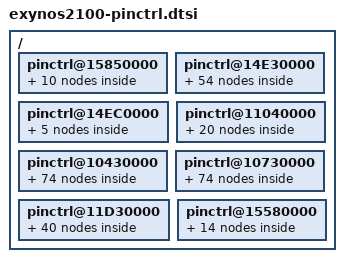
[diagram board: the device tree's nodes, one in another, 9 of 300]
/*
 * Samsung's Exynos2100 SoC pin-mux and pin-config device tree source
 *
 * Copyright (c) 2019 Samsung Electronics Co., Ltd.
 *		http://www.samsung.com
 *
 * Samsung's Exynos2100 SoC pin-mux and pin-config options are listed as device
 * tree nodes are listed in this file.
 *
 * This program is free software; you can redistribute it and/or modify
 * it under the terms of the GNU General Public License version 2 as
 * published by the Free Software Foundation.
*/

/ {
	/* ALIVE */
	pinctrl@15850000 {
		gpq0: gpq0 {
			gpio-controller;
			#gpio-cells = <2>;
		};
		gpq1: gpq1 {
			gpio-controller;
			#gpio-cells = <2>;
		};
		gpq2: gpq2 {
			gpio-controller;
			#gpio-cells = <2>;
		};
		gpb5: gpb5 {
			gpio-controller;
			#gpio-cells = <2>;
		};

		/* USI_UART_BT */
		uart1_bus_single: uart1-bus {
			samsung,pins = "gpq0-3", "gpq0-2", "gpq0-1", "gpq0-0";
			samsung,pin-function = <2>;
			samsung,pin-pud = <3>;
		};

		uart1_bus_rts: uart1-bus-rts {
			samsung,pins = "gpq0-2";
			samsung,pin-function = <1>;
			samsung,pin-pud = <0>;
			samsung,pin-val = <1>;
		};

		uart1_bus_tx_dat: uart1-bus-tx-dat {
			samsung,pins = "gpq0-1";
			samsung,pin-val = <1>;
		};

		uart1_bus_tx_con: uart1-bus-tx-con {
			samsung,pins = "gpq0-1";
			samsung,pin-function = <1>;
		};

		aud_i2s5_bus:aud-i2s5-bus {
			samsung,pins = "gpb5-0", "gpb5-1", "gpb5-2", "gpb5-3";
			samsung,pin-function = <3>;
			samsung,pin-pud = <0>;
		};

		aud_i2s5_idle:aud-i2s5-idle {
			samsung,pins = "gpb5-0", "gpb5-1", "gpb5-2", "gpb5-3";
			samsung,pin-function = <0>;
			samsung,pin-pud = <1>;
		};
	};

	/* CMGP */
	pinctrl@14E30000{
		gpm0: gpm0 {
			gpio-controller;
			#gpio-cells = <2>;

			interrupt-controller;
			#interrupt-cells = <2>;
			interrupt-parent = <&gic>;
			interrupts = <GIC_SPI INTREQ__EXT_INTM00 IRQ_TYPE_LEVEL_HIGH>,
				     <GIC_SPI INTREQ__EXT_INTM01 IRQ_TYPE_LEVEL_HIGH>;
		};

		gpm1: gpm1 {
			gpio-controller;
			#gpio-cells = <2>;

			interrupt-controller;
			#interrupt-cells = <2>;
			interrupt-parent = <&gic>;
			interrupts = <GIC_SPI INTREQ__EXT_INTM02 IRQ_TYPE_LEVEL_HIGH>,
				     <GIC_SPI INTREQ__EXT_INTM03 IRQ_TYPE_LEVEL_HIGH>;
		};

		gpm2: gpm2 {
			gpio-controller;
			#gpio-cells = <2>;

			interrupt-controller;
			#interrupt-cells = <2>;
			interrupt-parent = <&gic>;
			interrupts = <GIC_SPI INTREQ__EXT_INTM04 IRQ_TYPE_LEVEL_HIGH>,
				     <GIC_SPI INTREQ__EXT_INTM05 IRQ_TYPE_LEVEL_HIGH>;
		};

		gpm3: gpm3 {
			gpio-controller;
			#gpio-cells = <2>;

			interrupt-controller;
			#interrupt-cells = <2>;
			interrupt-parent = <&gic>;
			interrupts = <GIC_SPI INTREQ__EXT_INTM06 IRQ_TYPE_LEVEL_HIGH>,
				     <GIC_SPI INTREQ__EXT_INTM07 IRQ_TYPE_LEVEL_HIGH>;
		};

		gpm4: gpm4 {
			gpio-controller;
			#gpio-cells = <2>;

			interrupt-controller;
			#interrupt-cells = <2>;
			interrupt-parent = <&gic>;
			interrupts = <GIC_SPI INTREQ__EXT_INTM08 IRQ_TYPE_LEVEL_HIGH>,
				     <GIC_SPI INTREQ__EXT_INTM09 IRQ_TYPE_LEVEL_HIGH>;
		};

		gpm5: gpm5 {
			gpio-controller;
			#gpio-cells = <2>;

			interrupt-controller;
			#interrupt-cells = <2>;
			interrupt-parent = <&gic>;
			interrupts = <GIC_SPI INTREQ__EXT_INTM10 IRQ_TYPE_LEVEL_HIGH>,
				     <GIC_SPI INTREQ__EXT_INTM11 IRQ_TYPE_LEVEL_HIGH>;
		};

		gpm6: gpm6 {
			gpio-controller;
			#gpio-cells = <2>;

			interrupt-controller;
			#interrupt-cells = <2>;
			interrupt-parent = <&gic>;
			interrupts = <GIC_SPI INTREQ__EXT_INTM12 IRQ_TYPE_LEVEL_HIGH>,
				     <GIC_SPI INTREQ__EXT_INTM13 IRQ_TYPE_LEVEL_HIGH>;
		};

		gpm7: gpm7 {
			gpio-controller;
			#gpio-cells = <2>;

			interrupt-controller;
			#interrupt-cells = <2>;
			interrupt-parent = <&gic>;
			interrupts = <GIC_SPI INTREQ__EXT_INTM14 IRQ_TYPE_LEVEL_HIGH>,
				     <GIC_SPI INTREQ__EXT_INTM15 IRQ_TYPE_LEVEL_HIGH>;
		};

		gpm8: gpm8 {
			gpio-controller;
			#gpio-cells = <2>;

			interrupt-controller;
			#interrupt-cells = <2>;
			interrupt-parent = <&gic>;
			interrupts = <GIC_SPI INTREQ__EXT_INTM16 IRQ_TYPE_LEVEL_HIGH>;
		};

		gpm9: gpm9 {
			gpio-controller;
			#gpio-cells = <2>;

			interrupt-controller;
			#interrupt-cells = <2>;
			interrupt-parent = <&gic>;
			interrupts = <GIC_SPI INTREQ__EXT_INTM17 IRQ_TYPE_LEVEL_HIGH>;
		};

		gpm10: gpm10 {
			gpio-controller;
			#gpio-cells = <2>;

			interrupt-controller;
			#interrupt-cells = <2>;
			interrupt-parent = <&gic>;
			interrupts = <GIC_SPI INTREQ__EXT_INTM18 IRQ_TYPE_LEVEL_HIGH>;
		};

		gpm11: gpm11 {
			gpio-controller;
			#gpio-cells = <2>;

			interrupt-controller;
			#interrupt-cells = <2>;
			interrupt-parent = <&gic>;
			interrupts = <GIC_SPI INTREQ__EXT_INTM19 IRQ_TYPE_LEVEL_HIGH>;
		};

		gpm12: gpm12 {
			gpio-controller;
			#gpio-cells = <2>;

			interrupt-controller;
			#interrupt-cells = <2>;
			interrupt-parent = <&gic>;
			interrupts = <GIC_SPI INTREQ__EXT_INTM20 IRQ_TYPE_LEVEL_HIGH>;
		};

		gpm13: gpm13 {
			gpio-controller;
			#gpio-cells = <2>;

			interrupt-controller;
			#interrupt-cells = <2>;
			interrupt-parent = <&gic>;
			interrupts = <GIC_SPI INTREQ__EXT_INTM21 IRQ_TYPE_LEVEL_HIGH>;
		};

		gpm14: gpm14 {
			gpio-controller;
			#gpio-cells = <2>;

			interrupt-controller;
			#interrupt-cells = <2>;
			interrupt-parent = <&gic>;
			interrupts = <GIC_SPI INTREQ__EXT_INTM22 IRQ_TYPE_LEVEL_HIGH>;
		};

		gpm15: gpm15 {
			gpio-controller;
			#gpio-cells = <2>;

			interrupt-controller;
			#interrupt-cells = <2>;
			interrupt-parent = <&gic>;
			interrupts = <GIC_SPI INTREQ__EXT_INTM23 IRQ_TYPE_LEVEL_HIGH>;
		};

		gpm16: gpm16 {
			gpio-controller;
			#gpio-cells = <2>;

			interrupt-controller;
			#interrupt-cells = <2>;
			interrupt-parent = <&gic>;
			interrupts = <GIC_SPI INTREQ__EXT_INTM24 IRQ_TYPE_LEVEL_HIGH>;
		};

		gpm17: gpm17 {
			gpio-controller;
			#gpio-cells = <2>;

			interrupt-controller;
			#interrupt-cells = <2>;
			interrupt-parent = <&gic>;
			interrupts = <GIC_SPI INTREQ__EXT_INTM25 IRQ_TYPE_LEVEL_HIGH>;
		};

		gpm18: gpm18 {
			gpio-controller;
			#gpio-cells = <2>;

			interrupt-controller;
			#interrupt-cells = <2>;
			interrupt-parent = <&gic>;
			interrupts = <GIC_SPI INTREQ__EXT_INTM26 IRQ_TYPE_LEVEL_HIGH>;
		};

		gpm19: gpm19 {
			gpio-controller;
			#gpio-cells = <2>;

			interrupt-controller;
			#interrupt-cells = <2>;
			interrupt-parent = <&gic>;
			interrupts = <GIC_SPI INTREQ__EXT_INTM27 IRQ_TYPE_LEVEL_HIGH>;
		};

		gpm20: gpm20 {
			gpio-controller;
			#gpio-cells = <2>;

			interrupt-controller;
			#interrupt-cells = <2>;
			interrupt-parent = <&gic>;
			interrupts = <GIC_SPI INTREQ__EXT_INTM28 IRQ_TYPE_LEVEL_HIGH>;
		};

		gpm21: gpm21 {
			gpio-controller;
			#gpio-cells = <2>;

			interrupt-controller;
			#interrupt-cells = <2>;
			interrupt-parent = <&gic>;
			interrupts = <GIC_SPI INTREQ__EXT_INTM29 IRQ_TYPE_LEVEL_HIGH>;
		};

		gpm22: gpm22 {
			gpio-controller;
			#gpio-cells = <2>;

			interrupt-controller;
			#interrupt-cells = <2>;
			interrupt-parent = <&gic>;
			interrupts = <GIC_SPI INTREQ__EXT_INTM30 IRQ_TYPE_LEVEL_HIGH>;
		};

		gpm23: gpm23 {
			gpio-controller;
			#gpio-cells = <2>;

			interrupt-controller;
			#interrupt-cells = <2>;
			interrupt-parent = <&gic>;
			interrupts = <GIC_SPI INTREQ__EXT_INTM31 IRQ_TYPE_LEVEL_HIGH>;
		};

		gpm24: gpm24 {
			gpio-controller;
			#gpio-cells = <2>;

			interrupt-controller;
			#interrupt-cells = <2>;
			interrupt-parent = <&gic>;
			interrupts = <GIC_SPI INTREQ__EXT_INTM32 IRQ_TYPE_LEVEL_HIGH>;
		};

		gpm25: gpm25 {
			gpio-controller;
			#gpio-cells = <2>;

			interrupt-controller;
			#interrupt-cells = <2>;
			interrupt-parent = <&gic>;
			interrupts = <GIC_SPI INTREQ__EXT_INTM33 IRQ_TYPE_LEVEL_HIGH>;
		};

		/* usi_cmgp00 */
		hsi2c38_bus: hsi2c38-bus {
			samsung,pins = "gpm0-0", "gpm0-1";
			samsung,pin-function = <2>;
			samsung,pin-pud = <0>;
			samsung,pin-drv = <0>;
		};

		/* usi_cmgp00_i2c */
		hsi2c39_bus: hsi2c39-bus {
			samsung,pins = "gpm1-0", "gpm1-1";
			samsung,pin-function = <3>;
			samsung,pin-pud = <0>;
			samsung,pin-drv = <0>;
		};

		/* usi_cmgp01 */
		hsi2c40_bus: hsi2c40-bus {
			samsung,pins = "gpm2-0", "gpm2-1";
			samsung,pin-function = <2>;
			samsung,pin-pud = <0>;
			samsung,pin-drv = <0>;
		};

		/* usi_cmgp01_i2c */
		hsi2c41_bus: hsi2c41-bus {
			samsung,pins = "gpm3-0", "gpm3-1";
			samsung,pin-function = <3>;
			samsung,pin-pud = <0>;
			samsung,pin-drv = <0>;
		};

		/* usi_cmgp02 */
		hsi2c42_bus: hsi2c42-bus {
			samsung,pins = "gpm4-0", "gpm4-1";
			samsung,pin-function = <2>;
			samsung,pin-pud = <0>;
			samsung,pin-drv = <0>;
		};

		/* usi_cmgp02_i2c */
		hsi2c43_bus: hsi2c43-bus {
			samsung,pins = "gpm5-0", "gpm5-1";
			samsung,pin-function = <3>;
			samsung,pin-pud = <0>;
			samsung,pin-drv = <0>;
		};

		/* usi_cmgp03 */
		hsi2c44_bus: hsi2c44-bus {
			samsung,pins = "gpm6-0", "gpm6-1";
			samsung,pin-function = <2>;
			samsung,pin-pud = <0>;
			samsung,pin-drv = <0>;
		};

		/* usi_cmgp03_i2c */
		hsi2c45_bus: hsi2c45-bus {
			samsung,pins = "gpm7-0", "gpm7-1";
			samsung,pin-function = <3>;
			samsung,pin-pud = <0>;
			samsung,pin-drv = <0>;
		};

		/* spi usi_cmgp00 */
		spi19_bus: spi19-bus {
			samsung,pins = "gpm0-0", "gpm0-1", "gpm1-0";
			samsung,pin-function = <2>;
			samsung,pin-pud = <0>;
			samsung,pin-drv = <0>;
		};

		spi19_cs: spi19-cs {
			samsung,pins = "gpm1-1";
			samsung,pin-function = <1>;
			samsung,pin-pud = <0>;
			samsung,pin-drv = <0>;
		};

		spi19_cs_func: spi19-cs-func {
			samsung,pins = "gpm1-1";
			samsung,pin-function = <2>;
			samsung,pin-pud = <0>;
			samsung,pin-drv = <0>;
		};

		/* spi usi_cmgp01 */
		spi20_bus: spi20-bus {
			samsung,pins = "gpm2-0", "gpm2-1", "gpm3-0";
			samsung,pin-function = <2>;
			samsung,pin-pud = <0>;
			samsung,pin-drv = <0>;
		};

		spi20_cs: spi20-cs {
			samsung,pins = "gpm3-1";
			samsung,pin-function = <1>;
			samsung,pin-pud = <0>;
			samsung,pin-drv = <0>;
		};

		spi20_cs_func: spi20-cs-func {
			samsung,pins = "gpm3-1";
			samsung,pin-function = <2>;
			samsung,pin-pud = <0>;
			samsung,pin-drv = <0>;
		};

		/* spi usi_cmgp02 */
		spi21_bus: spi21-bus {
			samsung,pins = "gpm4-0", "gpm4-1", "gpm5-0";
			samsung,pin-function = <2>;
			samsung,pin-pud = <0>;
			samsung,pin-drv = <0>;
		};

		spi21_cs: spi21-cs {
			samsung,pins = "gpm5-1";
			samsung,pin-function = <1>;
			samsung,pin-pud = <0>;
			samsung,pin-drv = <0>;
		};

		spi21_cs_func: spi21-cs-func {
			samsung,pins = "gpm5-1";
			samsung,pin-function = <2>;
			samsung,pin-pud = <0>;
			samsung,pin-drv = <0>;
		};

		/* spi usi_cmgp03 */
		spi22_bus: spi22-bus {
			samsung,pins = "gpm6-0", "gpm6-1", "gpm7-0";
			samsung,pin-function = <2>;
			samsung,pin-pud = <0>;
			samsung,pin-drv = <0>;
		};

		spi22_cs: spi22-cs {
			samsung,pins = "gpm7-1";
			samsung,pin-function = <1>;
			samsung,pin-pud = <0>;
			samsung,pin-drv = <0>;
		};

		spi22_cs_func: spi22-cs-func {
			samsung,pins = "gpm7-1";
			samsung,pin-function = <2>;
			samsung,pin-pud = <0>;
			samsung,pin-drv = <0>;
		};

		/* usi_cmgp00_uart */
		uart21_bus_single: uart21-bus {
			samsung,pins = "gpm0-0", "gpm0-1", "gpm2-0", "gpm2-1";
			samsung,pin-function = <2>;
			samsung,pin-pud = <0>;
		};

		uart21_bus_dual: uart21-bus-dual {
			samsung,pins = "gpm0-0", "gpm0-1";
			samsung,pin-function = <2>;
			samsung,pin-pud = <0>;
		};

		/* usi_cmgp01_uart */
		uart22_bus_single: uart22-bus {
			samsung,pins = "gpm3-0", "gpm3-1", "gpm4-0", "gpm4-1";
			samsung,pin-function = <2>;
			samsung,pin-pud = <0>;
		};

		uart22_bus_dual: uart22-bus-dual {
			samsung,pins = "gpm3-0", "gpm3-1";
			samsung,pin-function = <2>;
			samsung,pin-pud = <0>;
		};

		/* usi_cmgp02_uart */
		uart23_bus_single: uart23-bus {
			samsung,pins = "gpm5-0", "gpm5-1", "gpm6-0", "gpm6-1";
			samsung,pin-function = <2>;
			samsung,pin-pud = <0>;
		};

		uart23_bus_dual: uart23-bus-dual {
			samsung,pins = "gpm5-0", "gpm5-1";
			samsung,pin-function = <2>;
			samsung,pin-pud = <0>;
		};

		/* usi_cmgp03_uart */
		uart24_bus_single: uart24-bus {
			samsung,pins = "gpm7-0", "gpm7-1", "gpm8-0", "gpm8-1";
			samsung,pin-function = <2>;
			samsung,pin-pud = <0>;
		};

		uart24_bus_dual: uart24-bus-dual {
			samsung,pins = "gpm7-0", "gpm7-1";
			samsung,pin-function = <2>;
			samsung,pin-pud = <0>;
		};
	};

	/* CMGPEINT */
	pinctrl@14EC0000{
		gpa0: gpa0 {
			gpio-controller;
			#gpio-cells = <2>;

			interrupt-controller;
			#interrupt-cells = <3>;
			interrupt-parent = <&gic>;
			interrupts = <GIC_SPI EXT_INTA0_OUT0 IRQ_TYPE_LEVEL_HIGH>, <GIC_SPI EXT_INTA0_OUT1 IRQ_TYPE_LEVEL_HIGH>,
				     <GIC_SPI EXT_INTA0_OUT2 IRQ_TYPE_LEVEL_HIGH>, <GIC_SPI EXT_INTA0_OUT3 IRQ_TYPE_LEVEL_HIGH>,
				     <GIC_SPI EXT_INTA0_OUT4 IRQ_TYPE_LEVEL_HIGH>, <GIC_SPI EXT_INTA0_OUT5 IRQ_TYPE_LEVEL_HIGH>,
				     <GIC_SPI EXT_INTA0_OUT6 IRQ_TYPE_LEVEL_HIGH>, <GIC_SPI EXT_INTA0_OUT7 IRQ_TYPE_LEVEL_HIGH>;
		};

		gpa1: gpa1 {
			gpio-controller;
			#gpio-cells = <2>;

			interrupt-controller;
			#interrupt-cells = <3>;
			interrupt-parent = <&gic>;
			interrupts = <GIC_SPI EXT_INTA1_OUT0 IRQ_TYPE_LEVEL_HIGH>, <GIC_SPI EXT_INTA1_OUT1 IRQ_TYPE_LEVEL_HIGH>,
				     <GIC_SPI EXT_INTA1_OUT2 IRQ_TYPE_LEVEL_HIGH>, <GIC_SPI EXT_INTA1_OUT3 IRQ_TYPE_LEVEL_HIGH>,
				     <GIC_SPI EXT_INTA1_OUT4 IRQ_TYPE_LEVEL_HIGH>, <GIC_SPI EXT_INTA1_OUT5 IRQ_TYPE_LEVEL_HIGH>,
				     <GIC_SPI EXT_INTA1_OUT6 IRQ_TYPE_LEVEL_HIGH>, <GIC_SPI EXT_INTA1_OUT7 IRQ_TYPE_LEVEL_HIGH>;
		};

		gpa2: gpa2 {
			gpio-controller;
			#gpio-cells = <2>;

			interrupt-controller;
			#interrupt-cells = <3>;
			interrupt-parent = <&gic>;
			interrupts = <GIC_SPI EXT_INTA2_OUT0 IRQ_TYPE_LEVEL_HIGH>, <GIC_SPI EXT_INTA2_OUT1 IRQ_TYPE_LEVEL_HIGH>,
				     <GIC_SPI EXT_INTA2_OUT2 IRQ_TYPE_LEVEL_HIGH>, <GIC_SPI EXT_INTA2_OUT3 IRQ_TYPE_LEVEL_HIGH>,
				     <GIC_SPI EXT_INTA2_OUT4 IRQ_TYPE_LEVEL_HIGH>, <GIC_SPI EXT_INTA2_OUT5 IRQ_TYPE_LEVEL_HIGH>,
				     <GIC_SPI EXT_INTA2_OUT6 IRQ_TYPE_LEVEL_HIGH>, <GIC_SPI EXT_INTA2_OUT7 IRQ_TYPE_LEVEL_HIGH>;
		};

		gpa3: gpa3 {
			gpio-controller;
			#gpio-cells = <2>;

			interrupt-controller;
			#interrupt-cells = <3>;
			interrupt-parent = <&gic>;
			interrupts = <GIC_SPI EXT_INTA3_OUT0 IRQ_TYPE_LEVEL_HIGH>, <GIC_SPI EXT_INTA3_OUT1 IRQ_TYPE_LEVEL_HIGH>,
				     <GIC_SPI EXT_INTA3_OUT2 IRQ_TYPE_LEVEL_HIGH>, <GIC_SPI EXT_INTA3_OUT3 IRQ_TYPE_LEVEL_HIGH>,
				     <GIC_SPI EXT_INTA3_OUT4 IRQ_TYPE_LEVEL_HIGH>, <GIC_SPI EXT_INTA3_OUT5 IRQ_TYPE_LEVEL_HIGH>,
				     <GIC_SPI EXT_INTA3_OUT6 IRQ_TYPE_LEVEL_HIGH>, <GIC_SPI EXT_INTA3_OUT7 IRQ_TYPE_LEVEL_HIGH>;
		};

		gpa4: gpa4 {
			gpio-controller;
			#gpio-cells = <2>;

			interrupt-controller;
			#interrupt-cells = <3>;
			interrupt-parent = <&gic>;
			interrupts = <GIC_SPI EXT_INTA4_OUT0 IRQ_TYPE_LEVEL_HIGH>, <GIC_SPI EXT_INTA4_OUT1 IRQ_TYPE_LEVEL_HIGH>;
		};
	};

	/* HSI1 */
	pinctrl@11040000 {
		gpf0: gpf0 {
			gpio-controller;
			#gpio-cells = <2>;

			interrupt-controller;
			#interrupt-cells = <2>;
		};

		gpf1: gpf1 {
			gpio-controller;
			#gpio-cells = <2>;

			interrupt-controller;
			#interrupt-cells = <2>;
		};

		gpf2: gpf2 {
			gpio-controller;
			#gpio-cells = <2>;

			interrupt-controller;
			#interrupt-cells = <2>;
		};

		pcie0_clkreq: pcie0_clkreq {
		      samsung,pins = "gpf0-0";
		      samsung,pin-function = <2>;
		      samsung,pin-pud = <3>;
		      samsung,pin-drv = <3>;
		      samsung,pin-con-pdn = <3>;
		      samsung,pin-pud-pdn = <3>;
		};

		pcie0_perst: pcie0_perst {
		     samsung,pins = "gpf0-1";
		     samsung,pin-function = <1>;
		     samsung,pin-drv = <3>;
		     samsung,pin-con-pdn = <3>;
		};

		pcie1_clkreq: pcie1_clkreq {
		      samsung,pins = "gpf0-2";
		      samsung,pin-function = <2>;
		      samsung,pin-pud = <3>;
		      samsung,pin-drv = <3>;
		      samsung,pin-con-pdn = <3>;
		      samsung,pin-pud-pdn = <3>;
		};

		pcie1_perst: pcie1_perst {
		     samsung,pins = "gpf0-3";
		     samsung,pin-function = <1>;
		     samsung,pin-drv = <3>;
		     samsung,pin-con-pdn = <3>;
		};

		ufs_rst_n: ufs-rst-n {
			samsung,pins = "gpf2-1";
			samsung,pin-function = <2>;
			samsung,pin-pud = <0>;
			samsung,pin-con-pdn = <3>;
			samsung,pin-pud-pdn = <0>;
		};

		ufs_refclk_out: ufs-refclk-out {
			samsung,pins = "gpf2-0";
			samsung,pin-function = <2>;
			samsung,pin-pud = <0>;
			samsung,pin-con-pdn = <3>;
			samsung,pin-drv = <1>;
			samsung,pin-pud-pdn = <0>;
		};

		sd2_clk: sd2-clk {
			samsung,pins = "gpf1-0";
			samsung,pin-function = <2>;
			samsung,pin-pud = <0>;
			samsung,pin-drv = <2>;
		};

		sd2_cmd: sd2-cmd {
			samsung,pins = "gpf1-1";
			samsung,pin-function = <2>;
			samsung,pin-pud = <3>;
			samsung,pin-drv = <2>;
		};

		sd2_bus1: sd2-bus-width1 {
			samsung,pins = "gpf1-2";
			samsung,pin-function = <2>;
			samsung,pin-pud = <3>;
			samsung,pin-drv = <2>;
		};

		sd2_bus4: sd2-bus-width4 {
			samsung,pins = "gpf1-3", "gpf1-4", "gpf1-5";
			samsung,pin-function = <2>;
			samsung,pin-pud = <3>;
			samsung,pin-drv = <2>;
		};

		sd2_clk_fast_slew_rate_1x: sd2-clk_fast_slew_rate_1x {
			samsung,pins = "gpf1-0";
			samsung,pin-function = <2>;
			samsung,pin-pud = <0>;
			samsung,pin-drv = <0>;
		};

		sd2_clk_fast_slew_rate_1_5x: sd2-clk_fast_slew_rate_1_5x {
			samsung,pins = "gpf1-0";
			samsung,pin-function = <2>;
			samsung,pin-pud = <0>;
			samsung,pin-drv = <1>;
		};

		sd2_clk_fast_slew_rate_2x: sd2-clk_fast_slew_rate_2x {
			samsung,pins = "gpf1-0";
			samsung,pin-function = <2>;
			samsung,pin-pud = <0>;
			samsung,pin-drv = <2>;
		};

		sd2_clk_fast_slew_rate_2_5x: sd2-clk_fast_slew_rate_2_5x {
			samsung,pins = "gpf1-0";
			samsung,pin-function = <2>;
			samsung,pin-pud = <0>;
			samsung,pin-drv = <3>;
		};

		sd2_clk_fast_slew_rate_3x: sd2-clk_fast_slew_rate_3x {
			samsung,pins = "gpf1-0";
			samsung,pin-function = <2>;
			samsung,pin-pud = <0>;
			samsung,pin-drv = <4>;
		};

		sd2_clk_fast_slew_rate_4x: sd2-clk_fast_slew_rate_4x {
			samsung,pins = "gpf1-0";
			samsung,pin-function = <2>;
			samsung,pin-pud = <0>;
			samsung,pin-drv = <5>;
		};

		sd2_pins_as_pdn: sd2-pins-as-pdn {
			samsung,pins = "gpf1-0", "gpf1-1", "gpf1-2", "gpf1-3", "gpf1-4", "gpf1-5";
			samsung,pin-function = <0>;
			samsung,pin-pud = <2>;
		};

	};

	/* PERIC0 */
	pinctrl@10430000 {
		gpp0: gpp0 {
			gpio-controller;
			#gpio-cells = <2>;

			interrupt-controller;
			#interrupt-cells = <2>;
		};

		gpp1: gpp1 {
			gpio-controller;
			#gpio-cells = <2>;

			interrupt-controller;
			#interrupt-cells = <2>;
		};

		gpp2: gpp2 {
			gpio-controller;
			#gpio-cells = <2>;

			interrupt-controller;
			#interrupt-cells = <2>;
		};

		gpp3: gpp3 {
			gpio-controller;
			#gpio-cells = <2>;

			interrupt-controller;
			#interrupt-cells = <2>;
		};

		gpp4: gpp4 {
			gpio-controller;
			#gpio-cells = <2>;

			interrupt-controller;
			#interrupt-cells = <2>;
		};

		gpp5: gpp5 {
			gpio-controller;
			#gpio-cells = <2>;

			interrupt-controller;
			#interrupt-cells = <2>;
		};

		gpp13: gpp13 {
			gpio-controller;
			#gpio-cells = <2>;

			interrupt-controller;
			#interrupt-cells = <2>;
		};

		gpp14: gpp14 {
			gpio-controller;
			#gpio-cells = <2>;

			interrupt-controller;
			#interrupt-cells = <2>;
		};

		gpp15: gpp15 {
			gpio-controller;
			#gpio-cells = <2>;

			interrupt-controller;
			#interrupt-cells = <2>;
		};

		gpg0: gpg0 {
			gpio-controller;
			#gpio-cells = <2>;

			interrupt-controller;
			#interrupt-cells = <2>;
		};

		/* USI_PERIC0_UART_DBG */
		uart0_bus: uart0-bus {
			samsung,pins = "gpg0-2", "gpg0-3";
			samsung,pin-function = <3>;
			samsung,pin-pud = <3>;
		};

		/* PERIC0 USI00 */
		hsi2c0_bus: hsi2c0-bus {
			samsung,pins = "gpp0-0", "gpp0-1";
			samsung,pin-function = <2>;
			samsung,pin-pud = <0>;
			samsung,pin-drv = <0>;
		};

		/* PERIC0 USI00_I2C */
		hsi2c1_bus: hsi2c1-bus {
			samsung,pins = "gpp0-2", "gpp0-3";
			samsung,pin-function = <3>;
			samsung,pin-pud = <0>;
			samsung,pin-drv = <0>;
		};

		/* PERIC0 USI01 */
		hsi2c2_bus: hsi2c2-bus {
			samsung,pins = "gpp1-0", "gpp1-1";
			samsung,pin-function = <2>;
			samsung,pin-pud = <0>;
			samsung,pin-drv = <0>;
		};

		/* PERIC0 USI01_I2C */
		hsi2c3_bus: hsi2c3-bus {
			samsung,pins = "gpp1-2", "gpp1-3";
			samsung,pin-function = <3>;
			samsung,pin-pud = <0>;
			samsung,pin-drv = <0>;
		};

		/* PERIC0 USI02 */
		hsi2c4_bus: hsi2c4-bus {
			samsung,pins = "gpp2-0", "gpp2-1";
			samsung,pin-function = <2>;
			samsung,pin-pud = <0>;
			samsung,pin-drv = <0>;
		};

		/* PERIC0 USI02_I2C */
		hsi2c5_bus: hsi2c5-bus {
			samsung,pins = "gpp2-2", "gpp2-3";
			samsung,pin-function = <3>;
			samsung,pin-pud = <0>;
			samsung,pin-drv = <0>;
		};

		/* PERIC0 USI03 */
		hsi2c6_bus: hsi2c6-bus {
			samsung,pins = "gpp3-0", "gpp3-1";
			samsung,pin-function = <2>;
			samsung,pin-pud = <0>;
			samsung,pin-drv = <0>;
		};

		/* PERIC0 USI03_I2C */
		hsi2c7_bus: hsi2c7-bus {
			samsung,pins = "gpp3-2", "gpp3-3";
			samsung,pin-function = <3>;
			samsung,pin-pud = <0>;
			samsung,pin-drv = <0>;
		};

		/* PERIC0 USI04 */
		hsi2c8_bus: hsi2c8-bus {
			samsung,pins = "gpp4-0", "gpp4-1";
			samsung,pin-function = <2>;
			samsung,pin-pud = <0>;
			samsung,pin-drv = <0>;
		};

		/* PERIC0 USI04_I2C */
		hsi2c9_bus: hsi2c9-bus {
			samsung,pins = "gpp4-2", "gpp4-3";
			samsung,pin-function = <3>;
			samsung,pin-pud = <0>;
			samsung,pin-drv = <0>;
		};

		/* PERIC0 USI05 */
		hsi2c10_bus: hsi2c10-bus {
			samsung,pins = "gpp5-0", "gpp5-1";
			samsung,pin-function = <2>;
			samsung,pin-pud = <0>;
			samsung,pin-drv = <0>;
		};

		/* PERIC0 USI05_I2C */
		hsi2c11_bus: hsi2c11-bus {
			samsung,pins = "gpp5-2", "gpp5-3";
			samsung,pin-function = <3>;
			samsung,pin-pud = <0>;
			samsung,pin-drv = <0>;
		};

		/* PERIC0 USI13 */
		hsi2c26_bus: hsi2c26-bus {
			samsung,pins = "gpp13-0", "gpp13-1";
			samsung,pin-function = <2>;
			samsung,pin-pud = <0>;
			samsung,pin-drv = <0>;
		};

		/* PERIC0 USI13_I2C */
		hsi2c27_bus: hsi2c27-bus {
			samsung,pins = "gpp13-2", "gpp13-3";
			samsung,pin-function = <3>;
			samsung,pin-pud = <0>;
			samsung,pin-drv = <0>;
		};

		/* PERIC0 USI14 */
		hsi2c28_bus: hsi2c28-bus {
			samsung,pins = "gpp14-0", "gpp14-1";
			samsung,pin-function = <2>;
			samsung,pin-pud = <0>;
			samsung,pin-drv = <0>;
		};

		/* PERIC0 USI14_I2C */
		hsi2c29_bus: hsi2c29-bus {
			samsung,pins = "gpp14-2", "gpp14-3";
			samsung,pin-function = <3>;
			samsung,pin-pud = <0>;
			samsung,pin-drv = <0>;
		};

		/* PERIC0 USI15 */
		hsi2c30_bus: hsi2c30-bus {
			samsung,pins = "gpp15-0", "gpp15-1";
			samsung,pin-function = <2>;
			samsung,pin-pud = <0>;
			samsung,pin-drv = <0>;
		};

		/* PERIC0 USI15_I2C */
		hsi2c31_bus: hsi2c31-bus {
			samsung,pins = "gpp15-2", "gpp15-3";
			samsung,pin-function = <3>;
			samsung,pin-pud = <0>;
			samsung,pin-drv = <0>;
		};

		/* SPI USI_PERIC0_USI00_SPI */
		spi0_bus: spi0-bus {
			samsung,pins = "gpp0-2", "gpp0-1", "gpp0-0";
			samsung,pin-function = <2>;
			samsung,pin-pud = <0>;
			samsung,pin-drv = <0>;
		};

		spi0_cs: spi0-cs {
			samsung,pins = "gpp0-3";
			samsung,pin-function = <1>;
			samsung,pin-pud = <0>;
			samsung,pin-drv = <0>;
		};

		spi0_cs_func: spi0-cs-func {
			samsung,pins = "gpp0-3";
			samsung,pin-function = <2>;
			samsung,pin-pud = <0>;
			samsung,pin-drv = <0>;
		};

		/* PERIC0 USI01_SPI */
		spi1_bus: spi1-bus {
			samsung,pins = "gpp1-2", "gpp1-1", "gpp1-0";
			samsung,pin-function = <2>;
			samsung,pin-pud = <0>;
			samsung,pin-drv = <0>;
		};

		spi1_cs: spi1-cs {
			samsung,pins = "gpp1-3";
			samsung,pin-function = <1>;
			samsung,pin-pud = <0>;
			samsung,pin-drv = <0>;
		};

		spi1_cs_func: spi1-cs-func {
			samsung,pins = "gpp1-3";
			samsung,pin-function = <2>;
			samsung,pin-pud = <0>;
			samsung,pin-drv = <0>;
		};

		/* PERIC0 USI02_SPI */
		spi2_bus: spi2-bus {
			samsung,pins = "gpp2-2", "gpp2-1", "gpp2-0";
			samsung,pin-function = <2>;
			samsung,pin-pud = <0>;
			samsung,pin-drv = <0>;
		};

		spi2_cs: spi2-cs {
			samsung,pins = "gpp2-3";
			samsung,pin-function = <1>;
			samsung,pin-pud = <0>;
			samsung,pin-drv = <0>;
		};

		spi2_cs_func: spi2-cs-func {
			samsung,pins = "gpp2-3";
			samsung,pin-function = <2>;
			samsung,pin-pud = <0>;
			samsung,pin-drv = <0>;
		};

		/* PERIC0 USI03_SPI */
		spi3_bus: spi3-bus {
			samsung,pins = "gpp3-2", "gpp3-1", "gpp3-0";
			samsung,pin-function = <2>;
			samsung,pin-pud = <0>;
			samsung,pin-drv = <0>;
		};

		spi3_cs: spi3-cs {
			samsung,pins = "gpp3-3";
			samsung,pin-function = <1>;
			samsung,pin-pud = <0>;
			samsung,pin-drv = <0>;
		};

		spi3_cs_func: spi3-cs-func {
			samsung,pins = "gpp3-3";
			samsung,pin-function = <2>;
			samsung,pin-pud = <0>;
			samsung,pin-drv = <0>;
		};

		/* PERIC0 USI04_SPI */
		spi4_bus: spi4-bus {
			samsung,pins = "gpp4-2", "gpp4-1", "gpp4-0";
			samsung,pin-function = <2>;
			samsung,pin-pud = <0>;
			samsung,pin-drv = <0>;
		};

		spi4_cs: spi4-cs {
			samsung,pins = "gpp4-3";
			samsung,pin-function = <1>;
			samsung,pin-pud = <0>;
			samsung,pin-drv = <0>;
		};

		spi4_cs_func: spi4-cs-func {
			samsung,pins = "gpp4-3";
			samsung,pin-function = <2>;
			samsung,pin-pud = <0>;
			samsung,pin-drv = <0>;
		};

		/* PERIC0 USI05_SPI */
		spi5_bus: spi5-bus {
			samsung,pins = "gpp5-2", "gpp5-1", "gpp5-0";
			samsung,pin-function = <2>;
			samsung,pin-pud = <0>;
			samsung,pin-drv = <0>;
		};

		spi5_cs: spi5-cs {
			samsung,pins = "gpp5-3";
			samsung,pin-function = <1>;
			samsung,pin-pud = <0>;
			samsung,pin-drv = <0>;
		};

		spi5_cs_func: spi5-cs-func {
			samsung,pins = "gpp5-3";
			samsung,pin-function = <2>;
			samsung,pin-pud = <0>;
			samsung,pin-drv = <0>;
		};

		/* PERIC0 USI13_SPI */
		spi13_bus: spi13-bus {
			samsung,pins = "gpp13-2", "gpp13-1", "gpp13-0";
			samsung,pin-function = <2>;
			samsung,pin-pud = <0>;
			samsung,pin-drv = <0>;
		};

		spi13_cs: spi13-cs {
			samsung,pins = "gpp13-3";
			samsung,pin-function = <1>;
			samsung,pin-pud = <0>;
			samsung,pin-drv = <0>;
		};

		spi13_cs_func: spi13-cs-func {
			samsung,pins = "gpp13-3";
			samsung,pin-function = <2>;
			samsung,pin-pud = <0>;
			samsung,pin-drv = <0>;
		};

		/* PERIC0 USI14_SPI */
		spi14_bus: spi14-bus {
			samsung,pins = "gpp14-2", "gpp14-1", "gpp14-0";
			samsung,pin-function = <2>;
			samsung,pin-pud = <0>;
			samsung,pin-drv = <0>;
		};

		spi14_cs: spi14-cs {
			samsung,pins = "gpp14-3";
			samsung,pin-function = <1>;
			samsung,pin-pud = <0>;
			samsung,pin-drv = <0>;
		};

		spi14_cs_func: spi14-cs-func {
			samsung,pins = "gpp14-3";
			samsung,pin-function = <2>;
			samsung,pin-pud = <0>;
			samsung,pin-drv = <0>;
		};

		/* PERIC0 USI15_SPI */
		spi15_bus: spi15-bus {
			samsung,pins = "gpp15-2", "gpp15-1", "gpp15-0";
			samsung,pin-function = <2>;
			samsung,pin-pud = <0>;
			samsung,pin-drv = <0>;
		};

		spi15_cs: spi15-cs {
			samsung,pins = "gpp15-3";
			samsung,pin-function = <1>;
			samsung,pin-pud = <0>;
			samsung,pin-drv = <0>;
		};

		spi15_cs_func: spi15-cs-func {
			samsung,pins = "gpp15-3";
			samsung,pin-function = <2>;
			samsung,pin-pud = <0>;
			samsung,pin-drv = <0>;
		};

		/* USI_PERIC0_USI00_UART */
		uart2_bus_single: uart2-bus {
			samsung,pins = "gpp0-0", "gpp0-1", "gpp0-2", "gpp0-3";
			samsung,pin-function = <2>;
			samsung,pin-pud = <0>;
		};

		uart2_bus_dual: uart2-bus-dual {
			samsung,pins = "gpp0-0", "gpp0-1";
			samsung,pin-function = <2>;
			samsung,pin-pud = <0>;
		};

		/* USI_PERIC0_USI01_UART */
		uart3_bus_single: uart3-bus {
			samsung,pins = "gpp1-0", "gpp1-1", "gpp1-2", "gpp1-3";
			samsung,pin-function = <2>;
			samsung,pin-pud = <0>;
		};

		uart3_bus_dual: uart3-bus-dual {
			samsung,pins = "gpp1-0", "gpp1-1";
			samsung,pin-function = <2>;
			samsung,pin-pud = <0>;
		};

		/* USI_PERIC0_USI02_UART */
		uart4_bus_single: uart4-bus {
			samsung,pins = "gpp2-0", "gpp2-1", "gpp2-2", "gpp2-3";
			samsung,pin-function = <2>;
			samsung,pin-pud = <0>;
		};

		uart4_bus_dual: uart4-bus-dual {
			samsung,pins = "gpp2-0", "gpp2-1";
			samsung,pin-function = <2>;
			samsung,pin-pud = <0>;
		};

		/* USI_PERIC0_USI03_UART */
		uart5_bus_single: uart5-bus {
			samsung,pins = "gpp3-0", "gpp3-1", "gpp3-2", "gpp3-3";
			samsung,pin-function = <2>;
			samsung,pin-pud = <0>;
		};

		uart5_bus_dual: uart5-bus-dual {
			samsung,pins = "gpp3-0", "gpp3-1";
			samsung,pin-function = <2>;
			samsung,pin-pud = <0>;
		};

		/* USI_PERIC0_USI04_UART */
		uart6_bus_single: uart6-bus {
			samsung,pins = "gpp4-0", "gpp4-1", "gpp4-2", "gpp4-3";
			samsung,pin-function = <2>;
			samsung,pin-pud = <0>;
		};

		uart6_bus_dual: uart6-bus-dual {
			samsung,pins = "gpp4-0", "gpp4-1";
			samsung,pin-function = <2>;
			samsung,pin-pud = <0>;
		};

		/* USI_PERIC0_USI05_UART */
		uart7_bus_single: uart7-bus {
			samsung,pins = "gpp5-0", "gpp5-1", "gpp5-2", "gpp5-3";
			samsung,pin-function = <2>;
			samsung,pin-pud = <0>;
		};

		uart7_bus_dual: uart7-bus-dual {
			samsung,pins = "gpp5-0", "gpp5-1";
			samsung,pin-function = <2>;
			samsung,pin-pud = <0>;
		};

		/* USI_PERIC0_USI13_UART */
		uart15_bus_single: uart15-bus {
			samsung,pins = "gpp13-0", "gpp13-1", "gpp13-2", "gpp13-3";
			samsung,pin-function = <2>;
			samsung,pin-pud = <0>;
		};

		uart15_bus_dual: uart15-bus-dual {
			samsung,pins = "gpp13-0", "gpp13-1";
			samsung,pin-function = <2>;
			samsung,pin-pud = <0>;
		};

		/* USI_PERIC0_USI14_UART */
		uart16_bus_single: uart16-bus {
			samsung,pins = "gpp14-0", "gpp14-1", "gpp14-2", "gpp14-3";
			samsung,pin-function = <2>;
			samsung,pin-pud = <0>;
		};

		uart16_bus_dual: uart16-bus-dual {
			samsung,pins = "gpp14-0", "gpp14-1";
			samsung,pin-function = <2>;
			samsung,pin-pud = <0>;
		};

		/* USI_PERIC0_USI15_UART */
		uart17_bus_single: uart17-bus {
			samsung,pins = "gpp15-0", "gpp15-1", "gpp15-2", "gpp15-3";
			samsung,pin-function = <2>;
			samsung,pin-pud = <0>;
		};

		uart17_bus_dual: uart17-bus-dual {
			samsung,pins = "gpp15-0", "gpp15-1";
			samsung,pin-function = <2>;
			samsung,pin-pud = <0>;
		};
	};

	/* PERIC1 */
	pinctrl@10730000 {
		gpb3: gpb3 {
			gpio-controller;
			#gpio-cells = <2>;

			interrupt-controller;
			#interrupt-cells = <2>;
		};

		gpb4: gpb4 {
			gpio-controller;
			#gpio-cells = <2>;

			interrupt-controller;
			#interrupt-cells = <2>;
		};

		gpp11: gpp11 {
			gpio-controller;
			#gpio-cells = <2>;

			interrupt-controller;
			#interrupt-cells = <2>;
		};

		gpp12: gpp12 {
			gpio-controller;
			#gpio-cells = <2>;

			interrupt-controller;
			#interrupt-cells = <2>;
		};

		gpp16: gpp16 {
			gpio-controller;
			#gpio-cells = <2>;

			interrupt-controller;
			#interrupt-cells = <2>;
		};

		gpp17: gpp17 {
			gpio-controller;
			#gpio-cells = <2>;

			interrupt-controller;
			#interrupt-cells = <2>;
		};

		gpp18: gpp18 {
			gpio-controller;
			#gpio-cells = <2>;

			interrupt-controller;
			#interrupt-cells = <2>;
		};

		gpg1: gpg1 {
			gpio-controller;
			#gpio-cells = <2>;

			interrupt-controller;
			#interrupt-cells = <2>;
		};

		gpg2: gpg2 {
			gpio-controller;
			#gpio-cells = <2>;

			interrupt-controller;
			#interrupt-cells = <2>;
		};

		gpb0: gpb0 {
			gpio-controller;
			#gpio-cells = <2>;

			interrupt-controller;
			#interrupt-cells = <2>;
		};

		gpb1: gpb1 {
			gpio-controller;
			#gpio-cells = <2>;

			interrupt-controller;
			#interrupt-cells = <2>;
		};

		gpb2: gpb2 {
			gpio-controller;
			#gpio-cells = <2>;

			interrupt-controller;
			#interrupt-cells = <2>;
		};


		/* peric1 usi11 */
		hsi2c22_bus: hsi2c22-bus {
			samsung,pins = "gpp11-0", "gpp11-1";
			samsung,pin-function = <2>;
			samsung,pin-pud = <0>;
			samsung,pin-drv = <0>;
		};

		/* peric1 usi11_i2c */
		hsi2c23_bus: hsi2c23-bus {
			samsung,pins = "gpp11-2", "gpp11-3";
			samsung,pin-function = <3>;
			samsung,pin-pud = <0>;
			samsung,pin-drv = <0>;
		};

		/* PERIC1 USI12 */
		hsi2c24_bus: hsi2c24-bus {
			samsung,pins = "gpp12-0", "gpp12-1";
			samsung,pin-function = <2>;
			samsung,pin-pud = <0>;
			samsung,pin-drv = <0>;
		};

		/* PERIC1 USI12_I2C */
		hsi2c25_bus: hsi2c25-bus {
			samsung,pins = "gpp12-2", "gpp12-3";
			samsung,pin-function = <3>;
			samsung,pin-pud = <0>;
			samsung,pin-drv = <0>;
		};

		/* PERIC1 USI16 */
		hsi2c32_bus: hsi2c32-bus {
			samsung,pins = "gpp16-0", "gpp16-1";
			samsung,pin-function = <2>;
			samsung,pin-pud = <0>;
			samsung,pin-drv = <0>;
		};

		/* PERIC1 USI16_I2C */
		hsi2c33_bus: hsi2c33-bus {
			samsung,pins = "gpp16-2", "gpp16-3";
			samsung,pin-function = <3>;
			samsung,pin-pud = <0>;
			samsung,pin-drv = <0>;
		};

		/* PERIC1 USI17 */
		hsi2c34_bus: hsi2c34-bus {
			samsung,pins = "gpp17-0", "gpp17-1";
			samsung,pin-function = <2>;
			samsung,pin-pud = <0>;
			samsung,pin-drv = <0>;
		};

		/* PERIC1 USI17_I2C */
		hsi2c35_bus: hsi2c35-bus {
			samsung,pins = "gpp17-2", "gpp17-3";
			samsung,pin-function = <3>;
			samsung,pin-pud = <0>;
			samsung,pin-drv = <0>;
		};

		/* PERIC1 USI18 */
		hsi2c36_bus: hsi2c36-bus {
			samsung,pins = "gpp18-0", "gpp18-1";
			samsung,pin-function = <2>;
			samsung,pin-pud = <0>;
			samsung,pin-drv = <0>;
		};

		/* PERIC1 USI18_I2C */
		hsi2c37_bus: hsi2c37-bus {
			samsung,pins = "gpp18-2", "gpp18-3";
			samsung,pin-function = <3>;
			samsung,pin-pud = <0>;
			samsung,pin-drv = <0>;
		};

		/* PERIC1 USI11_SPI */
		spi11_bus: spi11-bus {
			samsung,pins = "gpp11-2", "gpp11-1", "gpp11-0";
			samsung,pin-function = <2>;
			samsung,pin-pud = <0>;
			samsung,pin-drv = <0>;
		};

		spi11_cs: spi11-cs {
			samsung,pins = "gpp11-3";
			samsung,pin-function = <1>;
			samsung,pin-pud = <0>;
			samsung,pin-drv = <0>;
		};

		spi11_cs_func: spi11-cs-func {
			samsung,pins = "gpp11-3";
			samsung,pin-function = <2>;
			samsung,pin-pud = <0>;
			samsung,pin-drv = <0>;
		};

		/* PERIC1 USI12_SPI */
		spi12_bus: spi12-bus {
			samsung,pins = "gpp12-2", "gpp12-1", "gpp12-0";
			samsung,pin-function = <2>;
			samsung,pin-pud = <0>;
			samsung,pin-drv = <0>;
		};

		spi12_cs: spi12-cs {
			samsung,pins = "gpp12-3";
			samsung,pin-function = <1>;
			samsung,pin-pud = <0>;
			samsung,pin-drv = <0>;
		};

		spi12_cs_func: spi12-cs-func {
			samsung,pins = "gpp12-3";
			samsung,pin-function = <2>;
			samsung,pin-pud = <0>;
			samsung,pin-drv = <0>;
		};

		/* PERIC1 USI16_SPI */
		spi16_bus: spi16-bus {
			samsung,pins = "gpp16-2", "gpp16-1", "gpp16-0";
			samsung,pin-function = <2>;
			samsung,pin-pud = <0>;
			samsung,pin-drv = <0>;
		};

		spi16_cs: spi16-cs {
			samsung,pins = "gpp16-3";
			samsung,pin-function = <1>;
			samsung,pin-pud = <0>;
			samsung,pin-drv = <0>;
		};

		spi16_cs_func: spi16-cs-func {
			samsung,pins = "gpp16-3";
			samsung,pin-function = <2>;
			samsung,pin-pud = <0>;
			samsung,pin-drv = <0>;
		};

		/* PERIC1 USI17_SPI */
		spi17_bus: spi17-bus {
			samsung,pins = "gpp17-2", "gpp17-1", "gpp17-0";
			samsung,pin-function = <2>;
			samsung,pin-pud = <0>;
			samsung,pin-drv = <0>;
		};

		spi17_cs: spi17-cs {
			samsung,pins = "gpp17-3";
			samsung,pin-function = <1>;
			samsung,pin-pud = <0>;
			samsung,pin-drv = <0>;
		};

		spi17_cs_func: spi17-cs-func {
			samsung,pins = "gpp17-3";
			samsung,pin-function = <2>;
			samsung,pin-pud = <0>;
			samsung,pin-drv = <0>;
		};

		/* PERIC1 USI18_SPI */
		spi18_bus: spi18-bus {
			samsung,pins = "gpp18-2", "gpp18-1", "gpp18-0";
			samsung,pin-function = <2>;
			samsung,pin-pud = <0>;
			samsung,pin-drv = <0>;
		};

		spi18_cs: spi18-cs {
			samsung,pins = "gpp18-3";
			samsung,pin-function = <1>;
			samsung,pin-pud = <0>;
			samsung,pin-drv = <0>;
		};

		spi18_cs_func: spi18-cs-func {
			samsung,pins = "gpp18-3";
			samsung,pin-function = <2>;
			samsung,pin-pud = <0>;
			samsung,pin-drv = <0>;
		};

		/* USI_PERIC1_USI11_UART */
		uart13_bus_single: uart13-bus {
			samsung,pins = "gpp11-3", "gpp11-2", "gpp11-1", "gpp11-0";
			samsung,pin-function = <2>;
			samsung,pin-pud = <0>;
		};

		uart13_bus_dual: uart13-bus-dual {
			samsung,pins = "gpp11-0", "gpp11-1";
			samsung,pin-function = <2>;
			samsung,pin-pud = <0>;
		};

		/* USI_PERIC1_USI12_UART */
		uart14_bus_single: uart14-bus {
			samsung,pins = "gpp12-3", "gpp12-2", "gpp12-1", "gpp12-0";
			samsung,pin-function = <2>;
			samsung,pin-pud = <0>;
		};

		uart14_bus_dual: uart14-bus-dual {
			samsung,pins = "gpp12-0", "gpp12-1";
			samsung,pin-function = <2>;
			samsung,pin-pud = <0>;
		};

		/* USI_PERIC1_USI16_UART */
		uart18_bus_single: uart18-bus {
			samsung,pins = "gpp16-3", "gpp16-2", "gpp16-1", "gpp16-0";
			samsung,pin-function = <2>;
			samsung,pin-pud = <0>;
		};

		uart18_bus_dual: uart18-bus-dual {
			samsung,pins = "gpp16-0", "gpp16-1";
			samsung,pin-function = <2>;
			samsung,pin-pud = <0>;
		};

		/* USI_PERIC1_USI17_UART */
		uart19_bus_single: uart19-bus {
			samsung,pins = "gpp17-3", "gpp17-2", "gpp17-1", "gpp17-0";
			samsung,pin-function = <2>;
			samsung,pin-pud = <0>;
		};

		uart19_bus_dual: uart19-bus-dual {
			samsung,pins = "gpp17-0", "gpp17-1";
			samsung,pin-function = <2>;
			samsung,pin-pud = <0>;
		};

		/* USI_PERIC1_USI18_UART */
		uart20_bus_single: uart20-bus {
			samsung,pins = "gpp18-3", "gpp18-2", "gpp18-1", "gpp18-0";
			samsung,pin-function = <2>;
			samsung,pin-pud = <0>;
		};

		uart20_bus_dual: uart20-bus-dual {
			samsung,pins = "gpp18-0", "gpp18-1";
			samsung,pin-function = <2>;
			samsung,pin-pud = <0>;
		};

		aud_i2s0_bus:aud-i2s0-bus {
			samsung,pins = "gpb0-0", "gpb0-1", "gpb0-2", "gpb0-3";
			samsung,pin-function = <2>;
			samsung,pin-pud = <0>;
		};

		aud_i2s0_idle:aud-i2s0-idle {
			samsung,pins = "gpb0-0", "gpb0-1", "gpb0-2", "gpb0-3";
			samsung,pin-function = <0>;
			samsung,pin-pud = <1>;
		};

		aud_i2s1_bus:aud-i2s1-bus {
			samsung,pins = "gpb1-0", "gpb1-1", "gpb1-2", "gpb1-3";
			samsung,pin-function = <2>;
			samsung,pin-pud = <0>;
		};

		aud_i2s1_idle:aud-i2s1-idle {
			samsung,pins = "gpb1-0", "gpb1-1", "gpb1-2", "gpb1-3";
			samsung,pin-function = <0>;
			samsung,pin-pud = <1>;
		};

		aud_i2s2_bus:aud-i2s2-bus {
			samsung,pins = "gpb2-0", "gpb2-1", "gpb2-2", "gpb2-3";
			samsung,pin-function = <2>;
			samsung,pin-pud = <0>;
		};

		aud_i2s2_idle:aud-i2s2-idle {
			samsung,pins = "gpb2-0", "gpb2-1", "gpb2-2", "gpb2-3";
			samsung,pin-function = <0>;
			samsung,pin-pud = <1>;
		};

		aud_i2s3_bus:aud-i2s3-bus {
			samsung,pins = "gpb3-0", "gpb3-1", "gpb3-2", "gpb3-3";
			samsung,pin-function = <2>;
			samsung,pin-pud = <0>;
		};

		aud_i2s3_idle:aud-i2s3-idle {
			samsung,pins = "gpb3-0", "gpb3-1", "gpb3-2", "gpb3-3";
			samsung,pin-function = <0>;
			samsung,pin-pud = <1>;
		};

		aud_i2s4_bus:aud-i2s4-bus {
			samsung,pins = "gpb4-0", "gpb4-1", "gpb4-2", "gpb4-3";
			samsung,pin-function = <2>;
			samsung,pin-pud = <0>;
		};

		aud_i2s4_idle:aud-i2s4-idle {
			samsung,pins = "gpb4-0", "gpb4-1", "gpb4-2", "gpb4-3";
			samsung,pin-function = <0>;
			samsung,pin-pud = <1>;
		};

		aud_dsd_bus: aud-dsd-bus {
			samsung,pins = "gpb1-0", "gpb1-1", "gpb1-2";
			samsung,pin-function = <3>;
			samsung,pin-pud = <0>;
		};

		aud_dsd_idle: aud-dsd-idle {
			samsung,pins = "gpb1-0", "gpb1-1", "gpb1-2";
			samsung,pin-function = <0>;
			samsung,pin-pud = <1>;
		};

		decon_0_te_on: decon_0_te_on {
			samsung,pins = "gpg1-4";
			samsung,pin-function = <0xf>;
		};

		decon_0_te_off: decon_0_te_off {
			samsung,pins = "gpg1-4";
			samsung,pin-function = <0>;
		};

		sensor_mclk0_out: sensor-mclk0-out {
			samsung,pins = "gpg1-0";	/* CIS_CLK0 */
			samsung,pin-function = <1>;
			samsung,pin-pud = <1>;
			samsung,pin-drv = <0>;
		};

		sensor_mclk1_out: sensor-mclk1-out {
			samsung,pins = "gpg1-1";	/* CIS_CLK1 */
			samsung,pin-function = <1>;
			samsung,pin-pud = <1>;
			samsung,pin-drv = <0>;
		};

		sensor_mclk2_out: sensor-mclk2-out {
			samsung,pins = "gpg1-2";	/* CIS_CLK2 */
			samsung,pin-function = <1>;
			samsung,pin-pud = <1>;
			samsung,pin-drv = <0>;
		};

		sensor_mclk3_out: sensor-mclk3-out {
			samsung,pins = "gpg1-3";	/* CIS_CLK3 */
			samsung,pin-function = <1>;
			samsung,pin-pud = <1>;
			samsung,pin-drv = <0>;
		};

		sensor_mclk4_out: sensor-mclk4-out {
			samsung,pins = "gpg2-1";	/* CIS_CLK4 */
			samsung,pin-function = <1>;
			samsung,pin-pud = <1>;
			samsung,pin-drv = <0>;
		};

		sensor_mclk5_out: sensor-mclk5-out {
			samsung,pins = "gpg2-2";	/* CIS_CLK5 */
			samsung,pin-function = <1>;
			samsung,pin-pud = <1>;
			samsung,pin-drv = <0>;
		};

		sensor_mclk0_fn: sensor-mclk0-fn {
			samsung,pins = "gpg1-0";	/* CIS_CLK0 */
			samsung,pin-function = <2>;
			samsung,pin-pud = <0>;
			samsung,pin-drv = <0>;
		};

		sensor_mclk1_fn: sensor-mclk1-fn {
			samsung,pins = "gpg1-1";	/* CIS_CLK1 */
			samsung,pin-function = <2>;
			samsung,pin-pud = <0>;
			samsung,pin-drv = <0>;
		};

		sensor_mclk2_fn: sensor-mclk2-fn {
			samsung,pins = "gpg1-2";	/* CIS_CLK2 */
			samsung,pin-function = <2>;
			samsung,pin-pud = <0>;
			samsung,pin-drv = <0>;
		};

		sensor_mclk3_fn: sensor-mclk3-fn {
			samsung,pins = "gpg1-3";	/* CIS_CLK3 */
			samsung,pin-function = <2>;
			samsung,pin-pud = <0>;
			samsung,pin-drv = <0>;
		};

		sensor_mclk4_fn: sensor-mclk4-fn {
			samsung,pins = "gpg2-1";	/* CIS_CLK4 */
			samsung,pin-function = <2>;
			samsung,pin-pud = <0>;
			samsung,pin-drv = <0>;
		};

		sensor_mclk5_fn: sensor-mclk5-fn {
			samsung,pins = "gpg2-2";	/* CIS_CLK5 */
			samsung,pin-function = <2>;
			samsung,pin-pud = <0>;
			samsung,pin-drv = <0>;
		};

		ufs_boot_ldo: ufs-boot-ldo {
			samsung,pins = "gpg2-0";
			samsung,pin-function = <1>;
			samsung,pin-pud = <0>;
			samsung,pin-con-pdn = <3>;
			samsung,pin-pud-pdn = <0>;
		};
	};

	/* PERIC2 */
	pinctrl@11D30000 {
		gpp6: gpp6 {
			gpio-controller;
			#gpio-cells = <2>;

			interrupt-controller;
			#interrupt-cells = <2>;
		};

		gpp7: gpp7 {
			gpio-controller;
			#gpio-cells = <2>;

			interrupt-controller;
			#interrupt-cells = <2>;
		};

		gpp8: gpp8 {
			gpio-controller;
			#gpio-cells = <2>;

			interrupt-controller;
			#interrupt-cells = <2>;
		};

		gpp9: gpp9 {
			gpio-controller;
			#gpio-cells = <2>;

			interrupt-controller;
			#interrupt-cells = <2>;
		};

		gpp10: gpp10 {
			gpio-controller;
			#gpio-cells = <2>;

			interrupt-controller;
			#interrupt-cells = <2>;
		};

		/* PERIC2 USI06 */
		hsi2c12_bus: hsi2c12-bus {
			samsung,pins = "gpp6-0", "gpp6-1";
			samsung,pin-function = <2>;
			samsung,pin-pud = <0>;
			samsung,pin-drv = <0>;
		};

		/* PERIC2 USI06_I2C */
		hsi2c13_bus: hsi2c13-bus {
			samsung,pins = "gpp6-2", "gpp6-3";
			samsung,pin-function = <3>;
			samsung,pin-pud = <0>;
			samsung,pin-drv = <0>;
		};

		/* PERIC2 USI07 */
		hsi2c14_bus: hsi2c14-bus {
			samsung,pins = "gpp7-0", "gpp7-1";
			samsung,pin-function = <2>;
			samsung,pin-pud = <0>;
			samsung,pin-drv = <0>;
		};

		/* PERIC2 USI07_I2C */
		hsi2c15_bus: hsi2c15-bus {
			samsung,pins = "gpp7-2", "gpp7-3";
			samsung,pin-function = <3>;
			samsung,pin-pud = <0>;
			samsung,pin-drv = <0>;
		};

		/* PERIC2 USI08 */
		hsi2c16_bus: hsi2c16-bus {
			samsung,pins = "gpp8-0", "gpp8-1";
			samsung,pin-function = <2>;
			samsung,pin-pud = <0>;
			samsung,pin-drv = <0>;
		};

		/* PERIC2 USI08_I2C */
		hsi2c17_bus: hsi2c17-bus {
			samsung,pins = "gpp8-2", "gpp8-3";
			samsung,pin-function = <3>;
			samsung,pin-pud = <0>;
			samsung,pin-drv = <0>;
		};

		/* PERIC1 USI09 */
		hsi2c18_bus: hsi2c18-bus {
			samsung,pins = "gpp9-0", "gpp9-1";
			samsung,pin-function = <2>;
			samsung,pin-pud = <0>;
			samsung,pin-drv = <0>;
		};

		/* PERIC1 USI09_I2C */
		hsi2c19_bus: hsi2c19-bus {
			samsung,pins = "gpp9-2", "gpp9-3";
			samsung,pin-function = <3>;
			samsung,pin-pud = <0>;
			samsung,pin-drv = <0>;
		};

		/* PERIC1 USI10 */
		hsi2c20_bus: hsi2c20-bus {
			samsung,pins = "gpp10-0", "gpp10-1";
			samsung,pin-function = <2>;
			samsung,pin-pud = <0>;
			samsung,pin-drv = <0>;
		};

		/* PERIC1 USI10_I2C */
		hsi2c21_bus: hsi2c21-bus {
			samsung,pins = "gpp10-2", "gpp10-3";
			samsung,pin-function = <3>;
			samsung,pin-pud = <0>;
			samsung,pin-drv = <0>;
		};

		/* PERIC2 USI06_SPI */
		spi6_bus: spi6-bus {
			samsung,pins = "gpp6-2", "gpp6-1", "gpp6-0";
			samsung,pin-function = <2>;
			samsung,pin-pud = <0>;
			samsung,pin-drv = <0>;
		};

		spi6_cs: spi6-cs {
			samsung,pins = "gpp6-3";
			samsung,pin-function = <1>;
			samsung,pin-pud = <0>;
			samsung,pin-drv = <0>;
		};

		spi6_cs_func: spi6-cs-func {
			samsung,pins = "gpp6-3";
			samsung,pin-function = <2>;
			samsung,pin-pud = <0>;
			samsung,pin-drv = <0>;
		};

		/* PERIC2 USI07_SPI */
		spi7_bus: spi7-bus {
			samsung,pins = "gpp7-2", "gpp7-1", "gpp7-0";
			samsung,pin-function = <2>;
			samsung,pin-pud = <0>;
			samsung,pin-drv = <0>;
		};

		spi7_cs: spi7-cs {
			samsung,pins = "gpp7-3";
			samsung,pin-function = <1>;
			samsung,pin-pud = <0>;
			samsung,pin-drv = <0>;
		};

		spi7_cs_func: spi7-cs-func {
			samsung,pins = "gpp7-3";
			samsung,pin-function = <2>;
			samsung,pin-pud = <0>;
			samsung,pin-drv = <0>;
		};

		/* PERIC2 USI08_SPI */
		spi8_bus: spi8-bus {
			samsung,pins = "gpp8-2", "gpp8-1", "gpp8-0";
			samsung,pin-function = <2>;
			samsung,pin-pud = <0>;
			samsung,pin-drv = <0>;
		};

		spi8_cs: spi8-cs {
			samsung,pins = "gpp8-3";
			samsung,pin-function = <1>;
			samsung,pin-pud = <0>;
			samsung,pin-drv = <0>;
		};

		spi8_cs_func: spi8-cs-func {
			samsung,pins = "gpp8-3";
			samsung,pin-function = <2>;
			samsung,pin-pud = <0>;
			samsung,pin-drv = <0>;
		};

		/* PERIC1 USI09_SPI */
		spi9_bus: spi9-bus {
			samsung,pins = "gpp9-2", "gpp9-1", "gpp9-0";
			samsung,pin-function = <2>;
			samsung,pin-pud = <0>;
			samsung,pin-drv = <0>;
		};

		spi9_cs: spi9-cs {
			samsung,pins = "gpp9-3";
			samsung,pin-function = <1>;
			samsung,pin-pud = <0>;
			samsung,pin-drv = <0>;
		};

		spi9_cs_func: spi9-cs-func {
			samsung,pins = "gpp9-3";
			samsung,pin-function = <2>;
			samsung,pin-pud = <0>;
			samsung,pin-drv = <0>;
		};

		/* PERIC1 USI10_SPI */
		spi10_bus: spi10-bus {
			samsung,pins = "gpp10-2", "gpp10-1", "gpp10-0";
			samsung,pin-function = <2>;
			samsung,pin-pud = <0>;
			samsung,pin-drv = <0>;
		};

		spi10_cs: spi10-cs {
			samsung,pins = "gpp10-3";
			samsung,pin-function = <1>;
			samsung,pin-pud = <0>;
			samsung,pin-drv = <0>;
		};

		spi10_cs_func: spi10-cs-func {
			samsung,pins = "gpp10-3";
			samsung,pin-function = <2>;
			samsung,pin-pud = <0>;
			samsung,pin-drv = <0>;
		};

		/* USI_PERIC1_USI06_UART */
		uart8_bus_single: uart8-bus {
			samsung,pins = "gpp6-3", "gpp6-2", "gpp6-1", "gpp6-0";
			samsung,pin-function = <2>;
			samsung,pin-pud = <0>;
		};

		uart8_bus_dual: uart8-bus-dual {
			samsung,pins = "gpp6-0", "gpp6-1";
			samsung,pin-function = <2>;
			samsung,pin-pud = <0>;
		};

		/* USI_PERIC1_USI07_UART */
		uart9_bus_single: uart9-bus {
			samsung,pins = "gpp7-3", "gpp7-2", "gpp7-1", "gpp7-0";
			samsung,pin-function = <2>;
			samsung,pin-pud = <0>;
		};

		uart9_bus_dual: uart9-bus-dual {
			samsung,pins = "gpp7-0", "gpp7-1";
			samsung,pin-function = <2>;
			samsung,pin-pud = <0>;
		};

		/* USI_PERIC1_USI08_UART */
		uart10_bus_single: uart10-bus {
			samsung,pins = "gpp8-3", "gpp8-2", "gpp8-1", "gpp8-0";
			samsung,pin-function = <2>;
			samsung,pin-pud = <0>;
		};

		uart10_bus_dual: uart10-bus-dual {
			samsung,pins = "gpp8-0", "gpp8-1";
			samsung,pin-function = <2>;
			samsung,pin-pud = <0>;
		};

		/* USI_PERIC1_USI09_UART */
		uart11_bus_single: uart11-bus {
			samsung,pins = "gpp9-3", "gpp9-2", "gpp9-1", "gpp9-0";
			samsung,pin-function = <2>;
			samsung,pin-pud = <0>;
		};

		uart11_bus_dual: uart11-bus-dual {
			samsung,pins = "gpp9-0", "gpp9-1";
			samsung,pin-function = <2>;
			samsung,pin-pud = <0>;
		};

		/* USI_PERIC1_USI10_UART */
		uart12_bus_single: uart12-bus {
			samsung,pins = "gpp10-3", "gpp10-2", "gpp10-1", "gpp10-0";
			samsung,pin-function = <2>;
			samsung,pin-pud = <0>;
		};

		uart12_bus_dual: uart12-bus-dual {
			samsung,pins = "gpp10-0", "gpp10-1";
			samsung,pin-function = <2>;
			samsung,pin-pud = <0>;
		};
	};

	/* VTS */
	pinctrl@15580000 {
		gpv0: gpv0 {
			gpio-controller;
			#gpio-cells = <2>;

			interrupt-controller;
			#interrupt-cells = <2>;
		};

		dmic_bus_clk: dmic-bus-clk {
			samsung,pins = "gpv0-0";
			samsung,pin-function = <2>;
			samsung,pin-pud = <1>;
			samsung,pin-con-pdn = <2>;
		};

		dmic_bus_clk_idle: dmic-bus-clk-idle {
			samsung,pins = "gpv0-0";
			samsung,pin-function = <0>;
			samsung,pin-pud = <0>;
			samsung,pin-con-pdn = <2>;
		};

		dmic_bus_clk1: dmic-bus-clk1 {
			samsung,pins = "gpv0-1";
			samsung,pin-function = <2>;
			samsung,pin-pud = <1>;
			samsung,pin-con-pdn = <2>;
		};

		dmic_bus_clk1_idle: dmic-bus-clk1-idle {
			samsung,pins = "gpv0-1";
			samsung,pin-function = <0>;
			samsung,pin-pud = <0>;
			samsung,pin-con-pdn = <2>;
		};

		dmic_bus_clk2: dmic-bus-clk2 {
			samsung,pins = "gpv0-2";
			samsung,pin-function = <2>;
			samsung,pin-pud = <1>;
			samsung,pin-con-pdn = <2>;
		};

		dmic_bus_clk2_idle: dmic-bus-clk2-idle {
			samsung,pins = "gpv0-2";
			samsung,pin-function = <0>;
			samsung,pin-pud = <0>;
			samsung,pin-con-pdn = <2>;
		};

		dmic_pdm: dmic-pdm {
			samsung,pins = "gpv0-3";
			samsung,pin-function = <2>;
			samsung,pin-pud = <1>;
			samsung,pin-con-pdn = <2>;
		};

		amic_pdm: amic-pdm {
			samsung,pins = "gpv0-3";
			samsung,pin-function = <3>;
			samsung,pin-pud = <0>;
			samsung,pin-con-pdn = <2>;
		};

		dmic_pdm_idle: dmic-pdm-idle {
			samsung,pins = "gpv0-3";
			samsung,pin-function = <0>;
			samsung,pin-pud = <0>;
			samsung,pin-con-pdn = <2>;
		};

		dmic_pdm1_bus: dmic-pdm1-bus {
			samsung,pins = "gpv0-4";
			samsung,pin-function = <2>;
			samsung,pin-pud = <1>;
			samsung,pin-con-pdn = <2>;
		};

		dmic_pdm1_idle: dmic-pdm1-idle {
			samsung,pins = "gpv0-4";
			samsung,pin-function = <0>;
			samsung,pin-pud = <0>;
			samsung,pin-con-pdn = <2>;
		};

		dmic_pdm2_bus: dmic-pdm2-bus {
			samsung,pins = "gpv0-5";
			samsung,pin-function = <2>;
			samsung,pin-pud = <1>;
			samsung,pin-con-pdn = <2>;
		};

		dmic_pdm2_idle: dmic-pdm2-idle {
			samsung,pins = "gpv0-5";
			samsung,pin-function = <0>;
			samsung,pin-pud = <0>;
			samsung,pin-con-pdn = <2>;
		};
	};
};
